# f29h85x_hsm_rtdma_regs register map
Vendor: Texas Instruments
Peripheral module from a debugger description file (folder HSM).
Registers are 32-bit, read-only, no defined reset value unless marked. A register's access mark holds for its fields unless they carry their own. Offsets are as the file gives them; lines under a group give offsets from that group; [hi:lo] are bit positions; {n}, {i} and the like mark numbered series; 'fields as' and 'values as' point back to an identical list; <NAME> marks a mode.

## HSM_RTDMA — HSM RTDMA Registers
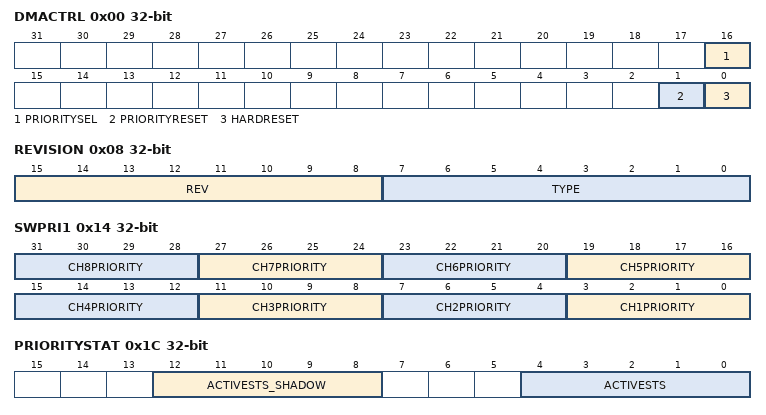
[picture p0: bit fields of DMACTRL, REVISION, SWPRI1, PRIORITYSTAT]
0x00 DMACTRL access per field
  [16] PRIORITYSEL rw, [1] PRIORITYRESET rw, [0] HARDRESET rw
0x04 DEBUGCTRL access per field
  [15] FREE rw
0x08 REVISION
  [15:8] REV, [7:0] TYPE
0x14 SWPRI1 rw
  [4n-1:4n-4] CH{n}PRIORITY (n=1..8)
0x18 SWPRI2 access not given
0x1C PRIORITYSTAT
  [12:8] ACTIVESTS_SHADOW, [4:0] ACTIVESTS
{0x20+4i} RESERVED_3[{i}] (i=0..7)
0x40 DMACFG_LOCK access per field
  [0] LOCK rw
0x44 DMACFG_COMMIT access per field
  [0] COMMIT rw
